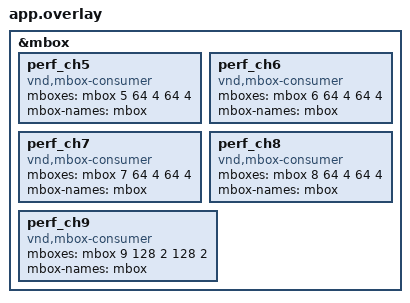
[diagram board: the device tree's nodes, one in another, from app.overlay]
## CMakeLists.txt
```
# SPDX-License-Identifier: Apache-2.0
# perf_test cpu2 (peer): minimal mbox echo companion for the perf_mbox suite.
# The cpu2 console/memory overlays must be injected before find_package().

cmake_minimum_required(VERSION 3.20.0)

set(EXTRA_DTC_OVERLAY_FILE
    ${CMAKE_CURRENT_SOURCE_DIR}/../../../common/cpu2_console_uart5.overlay;
    ${CMAKE_CURRENT_SOURCE_DIR}/../../../common/cpu2_mem_layout.overlay)

find_package(Zephyr REQUIRED HINTS $ENV{ZEPHYR_BASE})
project(cpu2_perf_peer)

target_sources(app PRIVATE src/main.c)

target_include_directories(app PRIVATE
    ${CMAKE_CURRENT_SOURCE_DIR}/../include
    ${CMAKE_CURRENT_SOURCE_DIR}/../../otbn_test/cpu1_otbn_test/src)

# Standalone build: both cores start together, so the 500-frame round trip has
# already happened when peer_alive runs.  The integrated sets never define this
# (their cpu1 sends frames only when the user asks for the perf_mbox suite).
target_compile_definitions(app PRIVATE ITEST_PEER_STANDALONE=1)

include(${CMAKE_CURRENT_SOURCE_DIR}/../../../common/common_sources.cmake)
```

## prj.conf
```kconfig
CONFIG_LOG=y
CONFIG_LOG_MODE_MINIMAL=y

CONFIG_ZTEST=y
CONFIG_ZTEST_ASSERT_VERBOSE=1
CONFIG_ZTEST_VERBOSE_OUTPUT=y
CONFIG_ZTEST_SUMMARY=n
# mbedtls_ls_otbn_rsa_modexp() puts four MBEDTLS_MPI_MAX_SIZE (1 KB) buffers
# on the stack; 4 KB overflowed on hardware (kernel panic).  Leave headroom
# for the OTBN call frame as well.
CONFIG_MAIN_STACK_SIZE=16384

CONFIG_PICOLIBC=y
CONFIG_NEWLIB_LIBC=n
CONFIG_MINIMAL_LIBC=n

CONFIG_MBOX=y
CONFIG_GPIO=y

# ---- OTBN crypto (cpu2 side; cpu1 runs the hardware engines) ----
CONFIG_MBEDTLS=y
CONFIG_MBEDTLS_BUILTIN=y
CONFIG_MBEDTLS_ENABLE_HEAP=y
CONFIG_MBEDTLS_HEAP_SIZE=32768
CONFIG_MBEDTLS_SHA256=y
CONFIG_MBEDTLS_SHA512=y
CONFIG_MBEDTLS_SHA224_SHA256_LINKEDSEMI_OTBN_ALT=y
CONFIG_MBEDTLS_SM3_LINKEDSEMI_OTBN_ALT=y
CONFIG_MBEDTLS_SHA384_SHA512_LINKEDSEMI_OTBN_ALT=y
CONFIG_MBEDTLS_RSA_LINKEDSEMI_OTBN_ALT=y
CONFIG_MBEDTLS_THREADING_LINKEDSEMI_ALT=y
CONFIG_LS_OTBN_OPERATION_TIMEOUT_MS=60000
```

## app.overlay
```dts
/*
 * SPDX-License-Identifier: Apache-2.0
 *
 * perf_test cpu2 (peer) overlay.  Console/memory layout come from the common
 * overlays injected in CMake; this file only adds the mbox consumers.
 * The mboxes first cell is the node's enumeration index under &mbox; the five
 * board-level consumers occupy 0..4, so this project appends 5/6.
 */

&mbox {
	perf_ch5: perf_ch5 {
		compatible = "vnd,mbox-consumer";
		mboxes = <&mbox 5 64 4 64 4>;
		mbox-names = "mbox";
	};

	perf_ch6: perf_ch6 {
		compatible = "vnd,mbox-consumer";
		mboxes = <&mbox 6 64 4 64 4>;
		mbox-names = "mbox";
	};

	perf_ch7: perf_ch7 {
		compatible = "vnd,mbox-consumer";
		mboxes = <&mbox 7 64 4 64 4>;
		mbox-names = "mbox";
	};

	perf_ch8: perf_ch8 {
		compatible = "vnd,mbox-consumer";
		mboxes = <&mbox 8 64 4 64 4>;
		mbox-names = "mbox";
	};

	perf_ch9: perf_ch9 {
		compatible = "vnd,mbox-consumer";
		mboxes = <&mbox 9 128 2 128 2>;
		mbox-names = "mbox";
	};
};
```

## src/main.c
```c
/*
 * SPDX-License-Identifier: Apache-2.0
 *
 * perf_test cpu2 peer.
 *
 * Two jobs:
 *   1. Echo 64-byte frames (perf_ch5 -> perf_ch6) for the cpu1 mbox test.
 *   2. Drive the flash proxy client (perf_ch7/perf_ch8): cpu2 asks the cpu1
 *      server to operate the qspi2 NOR and measures the end-to-end round trip.
 *
 * All test data is reported to cpu1 over perf_ch9 as text lines; cpu1 prints
 * them on its own console with a "PERF_TEST:CTRL:" envelope, so the whole
 * test record is visible on cpu1's UART only.  This core keeps just a boot
 * banner on its local UART.
 */
#include <zephyr/kernel.h>
#include <zephyr/drivers/mbox.h>
#include <errno.h>
#include <stdarg.h>
#include <stdio.h>
#include <string.h>

#if !defined(ITEST_PEER_NO_CRYPTO)
#include "mbedtls/sha256.h"
#include "mbedtls/sha512.h"
#include "mbedtls/sm3_alt.h"
#include "mbedtls_otbn_rsa_mbox.h"
#include "rsa_test_key.h"
#endif

#include "perf_proxy.h"
#include "perf_peer_tele.h"

#if defined(ITEST_ALL_PEER_ZTEST)
/* Provided by integrated/sets/itest_all/cpu2/src/peer_ztest.c: runs the OTBN
 * ztest suites that the integrated image links into this binary. */
extern int itest_all_peer_ztest_run(void);
#endif

#define PERF_MBOX_MAGIC  0x50455246u /* "PERF" */
#define PERF_READY_MAGIC 0x52454144u /* "READY" */
#define PERF_READY_DELAY_MS 600
#define PERF_FRAMES      500
#define TELE_FRAME_SIZE  128

struct perf_msg {
	uint32_t magic;
	uint32_t seq;
	uint8_t payload[56];
};

_Static_assert(sizeof(struct perf_msg) == 64,
	       "perf_msg must match the 64-byte mbox channel width");

/* ------------------------------------------------------------- mbox echo */

#if !defined(ITEST_PEER_NO_ECHO)
/* The integrated driver image keeps its own minimal echo (src/echo_peer.c) and
 * compiles this one out. */

static const struct mbox_dt_spec mbox_rx = MBOX_DT_SPEC_GET(DT_NODELABEL(perf_ch5), mbox);
static const struct mbox_dt_spec mbox_tx = MBOX_DT_SPEC_GET(DT_NODELABEL(perf_ch6), mbox);

K_MSGQ_DEFINE(echo_q, sizeof(struct perf_msg), 16, 4);

static volatile bool peer_started;
static volatile uint32_t echo_count;

static void mbox_rx_cb(const struct device *dev, mbox_channel_id_t channel,
		       void *user_data, struct mbox_msg *msg)
{
	ARG_UNUSED(dev);
	ARG_UNUSED(channel);
	ARG_UNUSED(user_data);

	if (msg == NULL || msg->data == NULL ||
	    msg->size < sizeof(struct perf_msg)) {
		return;
	}
	(void)k_msgq_put(&echo_q, msg->data, K_NO_WAIT);
}

static void echo_thread(void *a, void *b, void *c)
{
	ARG_UNUSED(a);
	ARG_UNUSED(b);
	ARG_UNUSED(c);

	peer_started = true;

	for (;;) {
		struct perf_msg m;
		struct mbox_msg out = {
			.data = &m,
			.size = sizeof(m),
		};

		if (k_msgq_get(&echo_q, &m, K_FOREVER) != 0) {
			continue;
		}

		for (int retry = 0; retry < 10; retry++) {
			if (mbox_send_dt(&mbox_tx, &out) == 0) {
				echo_count++;
				break;
			}
			k_msleep(1);
		}
	}
}

static K_THREAD_STACK_DEFINE(echo_stack, 2048);
static struct k_thread echo_td;
#endif /* !ITEST_PEER_NO_ECHO */

/* ------------------------------------------------------- telemetry sender */

static const struct mbox_dt_spec tele_tx = MBOX_DT_SPEC_GET(DT_NODELABEL(perf_ch9), mbox);

static int tele_send(const char *text)
{
	char buf[TELE_FRAME_SIZE] = { 0 };
	struct mbox_msg msg = {
		.data = buf,
		.size = sizeof(buf),
	};

	strncpy(buf, text, sizeof(buf) - 1);
	for (int i = 0; i < 200; i++) {
		if (mbox_send_dt(&tele_tx, &msg) == 0) {
			return 0;
		}
		k_msleep(1);
	}
	return -EIO;
}

/* Not static: the integrated image (integrated/sets/itest_all/cpu2) relays its
 * own result lines through the same sender. See include/perf_peer_tele.h. */
void tele_line(const char *fmt, ...)
{
	char buf[TELE_FRAME_SIZE];
	va_list ap;

	va_start(ap, fmt);
	vsnprintf(buf, sizeof(buf), fmt, ap);
	va_end(ap);
	(void)tele_send(buf);
}

/* --------------------------------------------------------- proxy client */

#if !defined(ITEST_PEER_NO_PROXY)
/* No flash-proxy channels (perf_ch7/ch8) in the integrated driver image: they
 * do not fit the 4 KB mbox carve-out next to rlog. */
static const struct mbox_dt_spec proxy_tx = MBOX_DT_SPEC_GET(DT_NODELABEL(perf_ch7), mbox);
static const struct mbox_dt_spec proxy_rx = MBOX_DT_SPEC_GET(DT_NODELABEL(perf_ch8), mbox);

/* One 4 KB read comes back as ~103 frames; hold a whole burst. */
K_MSGQ_DEFINE(proxy_q, sizeof(struct perf_proxy_msg), 128, 4);
static uint8_t proxy_buf[PERF_PROXY_SIZE];
static uint8_t proxy_verify[PERF_PROXY_SIZE];
static bool proxy_inited;

static void proxy_rx_cb(const struct device *dev, mbox_channel_id_t channel,
			void *user_data, struct mbox_msg *msg)
{
	ARG_UNUSED(dev);
	ARG_UNUSED(channel);
	ARG_UNUSED(user_data);

	if (msg == NULL || msg->data == NULL ||
	    msg->size < sizeof(struct perf_proxy_msg)) {
		return;
	}
	(void)k_msgq_put(&proxy_q, msg->data, K_NO_WAIT);
}

static int proxy_send(const struct perf_proxy_msg *m)
{
	struct mbox_msg msg = {
		.data = m,
		.size = sizeof(*m),
	};

	for (int i = 0; i < 200; i++) {
		if (mbox_send_dt(&proxy_tx, &msg) == 0) {
			return 0;
		}
		k_msleep(1);
	}
	return -EIO;
}

static int proxy_wait(struct perf_proxy_msg *m, int timeout_ms)
{
	return k_msgq_get(&proxy_q, m, K_MSEC(timeout_ms));
}

static int proxy_simple(uint8_t op, uint32_t offset, uint32_t len)
{
	struct perf_proxy_msg q = {
		.magic = PERF_PROXY_MAGIC,
		.op = op,
		.flags = PERF_PROXY_FLAG_LAST,
		.offset = offset,
		.len = len,
	};
	struct perf_proxy_msg r;

	k_msgq_purge(&proxy_q);
	if (proxy_send(&q) != 0) {
		return -EIO;
	}
	if (proxy_wait(&r, 2000) != 0) {
		return -ETIMEDOUT;
	}
	if (r.magic != PERF_PROXY_MAGIC) {
		return -EIO;
	}
	return (int)r.status;
}

static int proxy_read(uint32_t offset, uint32_t len, uint8_t *out)
{
	struct perf_proxy_msg q = {
		.magic = PERF_PROXY_MAGIC,
		.op = PERF_PROXY_READ,
		.flags = PERF_PROXY_FLAG_LAST,
		.offset = offset,
		.len = len,
	};
	uint32_t got = 0;

	k_msgq_purge(&proxy_q);
	if (proxy_send(&q) != 0) {
		return -EIO;
	}

	for (;;) {
		struct perf_proxy_msg r;

		if (proxy_wait(&r, 2000) != 0) {
			return -ETIMEDOUT;
		}
		if (r.magic != PERF_PROXY_MAGIC || r.op != PERF_PROXY_READ) {
			return -EIO;
		}
		if (r.status != 0) {
			return (int)r.status;
		}
		if (r.len > sizeof(r.data) || got + r.len > len) {
			return -EINVAL;
		}
		memcpy(&out[got], r.data, r.len);
		got += r.len;
		if (r.flags & PERF_PROXY_FLAG_LAST) {
			break;
		}
	}

	return got == len ? 0 : -EIO;
}

static int proxy_write(uint32_t offset, uint32_t len, const uint8_t *data)
{
	struct perf_proxy_msg r;

	k_msgq_purge(&proxy_q);
	for (uint32_t off = 0; off < len; off += PERF_PROXY_CHUNK) {
		uint32_t n = MIN(PERF_PROXY_CHUNK, len - off);
		struct perf_proxy_msg q = {
			.magic = PERF_PROXY_MAGIC,
			.op = PERF_PROXY_WRITE,
			.flags = (off + n >= len) ? PERF_PROXY_FLAG_LAST : 0,
			.offset = offset + off,
			.len = n,
		};

		memcpy(q.data, &data[off], n);
		if (proxy_send(&q) != 0) {
			return -EIO;
		}
	}

	if (proxy_wait(&r, 2000) != 0) {
		return -ETIMEDOUT;
	}
	if (r.magic != PERF_PROXY_MAGIC) {
		return -EIO;
	}
	return (int)r.status;
}

static void proxy_init_once(void)
{
	if (proxy_inited) {
		return;
	}

	(void)mbox_register_callback(proxy_rx.dev, proxy_rx.channel_id,
				     proxy_rx_cb, NULL);
	(void)mbox_set_enabled(proxy_rx.dev, proxy_rx.channel_id, 1);

	for (int i = 0; i < 50; i++) {
		if (proxy_simple(PERF_PROXY_PING, 0, 0) == 0) {
			proxy_inited = true;
			break;
		}
		k_msleep(100);
	}
}

#endif /* !ITEST_PEER_NO_PROXY */

/* -------------------------------------------------------------- test flow */

static void tele_perf(const char *module, const char *op,
		      uint32_t bytes, uint64_t us)
{
	double mb_s;

	if (us == 0) {
		us = 1;
	}
	mb_s = (double)bytes / (double)us;
	tele_line("PERF %s | %s | bytes=%u | MB/s=%.4f | KB/s=%.2f | us=%llu",
		  module, op, (unsigned)bytes, mb_s, mb_s * 1000.0,
		  (unsigned long long)us);
}

static void tele_ops(const char *module, const char *op,
		     uint32_t ops, uint64_t us)
{
	if (us == 0) {
		us = 1;
	}
	tele_line("PERF %s | %s | ops=%u | ops/s=%.2f | us=%llu",
		  module, op, (unsigned)ops,
		  (double)ops * 1000000.0 / (double)us,
		  (unsigned long long)us);
}

#if !defined(ITEST_PEER_NO_PROXY)
static bool run_proxy_erase(void)
{
	uint64_t t0, t1;
	int rc;

	proxy_init_once();
	if (!proxy_inited) {
		return false;
	}

	t0 = k_cycle_get_64();
	rc = proxy_simple(PERF_PROXY_ERASE, PERF_PROXY_OFFSET, PERF_PROXY_SIZE);
	t1 = k_cycle_get_64();

	tele_perf("flash_proxy", "erase", PERF_PROXY_SIZE, k_cyc_to_us_floor64(t1 - t0));
	return rc == 0;
}

static bool run_proxy_read(void)
{
	uint64_t t0, t1;
	int rc;

	proxy_init_once();
	if (!proxy_inited) {
		return false;
	}

	t0 = k_cycle_get_64();
	rc = proxy_read(PERF_PROXY_OFFSET, PERF_PROXY_SIZE, proxy_buf);
	t1 = k_cycle_get_64();

	tele_perf("flash_proxy", "read", PERF_PROXY_SIZE, k_cyc_to_us_floor64(t1 - t0));
	return rc == 0;
}

static bool run_proxy_write(void)
{
	uint64_t t0, t1;
	int rc;

	proxy_init_once();
	if (!proxy_inited) {
		return false;
	}

	for (size_t i = 0; i < PERF_PROXY_SIZE; i++) {
		proxy_buf[i] = (uint8_t)(i * 7u);
	}

	if (proxy_simple(PERF_PROXY_ERASE, PERF_PROXY_OFFSET,
			 PERF_PROXY_SIZE) != 0) {
		return false;
	}

	t0 = k_cycle_get_64();
	rc = proxy_write(PERF_PROXY_OFFSET, PERF_PROXY_SIZE, proxy_buf);
	t1 = k_cycle_get_64();

	tele_perf("flash_proxy", "write", PERF_PROXY_SIZE, k_cyc_to_us_floor64(t1 - t0));

	if (rc != 0) {
		return false;
	}
	if (proxy_read(PERF_PROXY_OFFSET, PERF_PROXY_SIZE, proxy_verify) != 0) {
		return false;
	}
	return memcmp(proxy_buf, proxy_verify, PERF_PROXY_SIZE) == 0;
}

#endif /* !ITEST_PEER_NO_PROXY */

#if defined(ITEST_PEER_STANDALONE)
/* Only meaningful standalone: there both cores start together, so cpu1 has
 * already pushed the 500 frames by the time this runs.  In an integrated image
 * cpu1 sends frames only when the user runs the perf_mbox suite, so this would
 * just burn its 30 s timeout and report a false FAIL. */
static bool run_peer_alive(void)
{
	int64_t deadline = k_uptime_get() + 30000;

	if (!peer_started) {
		return false;
	}

	while (echo_count < PERF_FRAMES && k_uptime_get() < deadline) {
		k_msleep(10);
	}
	return echo_count == PERF_FRAMES;
}
#endif /* ITEST_PEER_STANDALONE */

/* parse_ztest's native token form requires the duration suffix. */
static void report(const char *name, bool ok, int64_t elapsed_ms, bool *all_ok)
{
	tele_line("%s - %s in %.3f seconds", ok ? "PASS" : "FAIL", name,
		  (double)elapsed_ms / 1000.0);
	if (!ok) {
		*all_ok = false;
	}
}

/* ------------------------------------------------- OTBN crypto (cpu2) */

#if !defined(ITEST_PEER_NO_CRYPTO)
/* The integrated driver image (integrated/sets/itest_all/cpu2) leaves the
 * crypto out: it has no OTBN configuration, and crypto lives in the dedicated
 * itest_crypto set. */

#define CRYPTO_BUF_SIZE (KB(32) + 32)
static uint8_t crypto_buf[CRYPTO_BUF_SIZE] __aligned(32);
static const size_t crypto_sizes[] = { KB(1), KB(4), KB(16), KB(32) };

static bool digest_sha256(const uint8_t *in, size_t len, uint8_t out[32])
{
	mbedtls_sha256_context c;
	int rc;

	mbedtls_sha256_init(&c);
	rc = mbedtls_sha256_starts(&c, 0);
	rc |= mbedtls_sha256_update(&c, in, len);
	rc |= mbedtls_sha256_finish(&c, out);
	mbedtls_sha256_free(&c);
	return rc == 0;
}

static bool digest_sha512(const uint8_t *in, size_t len, uint8_t out[64])
{
	mbedtls_sha512_context c;
	int rc;

	mbedtls_sha512_init(&c);
	rc = mbedtls_sha512_starts(&c, 0);
	rc |= mbedtls_sha512_update(&c, in, len);
	rc |= mbedtls_sha512_finish(&c, out);
	mbedtls_sha512_free(&c);
	return rc == 0;
}

static bool digest_sm3(const uint8_t *in, size_t len, uint8_t out[32])
{
	mbedtls_sm3_context c;
	int rc;

	mbedtls_sm3_init(&c);
	rc = mbedtls_sm3_starts(&c);
	rc |= mbedtls_sm3_update(&c, in, len);
	rc |= mbedtls_sm3_finish(&c, out);
	mbedtls_sm3_free(&c);
	return rc == 0;
}

static bool run_sha256_otbn(bool unaligned)
{
	uint8_t ref[32], out[32];
	const char *name = unaligned ? "sha256_otbn_unaligned" : "sha256_otbn";

	memset(crypto_buf, 0x5A, sizeof(crypto_buf));
	for (size_t s = 0; s < ARRAY_SIZE(crypto_sizes); s++) {
		size_t size = crypto_sizes[s];
		const uint8_t *in = unaligned ? crypto_buf + 1 : crypto_buf;
		mbedtls_sha256_context c;
		uint64_t t0, t1;
		int rc;

		if (!digest_sha256(crypto_buf, size, ref)) {
			return false;
		}
		mbedtls_sha256_init(&c);
		rc = mbedtls_sha256_starts(&c, 0);
		t0 = k_cycle_get_64();
		rc |= mbedtls_sha256_update(&c, in, size);
		rc |= mbedtls_sha256_finish(&c, out);
		t1 = k_cycle_get_64();
		mbedtls_sha256_free(&c);
		if (rc != 0 || memcmp(ref, out, sizeof(out)) != 0) {
			return false;
		}
		tele_perf("crypto", name, size, k_cyc_to_us_floor64(t1 - t0));
	}
	return true;
}

static bool run_sha512_otbn(bool unaligned)
{
	uint8_t ref[64], out[64];
	const char *name = unaligned ? "sha512_otbn_unaligned" : "sha512_otbn";

	memset(crypto_buf, 0x5A, sizeof(crypto_buf));
	for (size_t s = 0; s < ARRAY_SIZE(crypto_sizes); s++) {
		size_t size = crypto_sizes[s];
		const uint8_t *in = unaligned ? crypto_buf + 1 : crypto_buf;
		mbedtls_sha512_context c;
		uint64_t t0, t1;
		int rc;

		if (!digest_sha512(crypto_buf, size, ref)) {
			return false;
		}
		mbedtls_sha512_init(&c);
		rc = mbedtls_sha512_starts(&c, 0);
		t0 = k_cycle_get_64();
		rc |= mbedtls_sha512_update(&c, in, size);
		rc |= mbedtls_sha512_finish(&c, out);
		t1 = k_cycle_get_64();
		mbedtls_sha512_free(&c);
		if (rc != 0 || memcmp(ref, out, sizeof(out)) != 0) {
			return false;
		}
		tele_perf("crypto", name, size, k_cyc_to_us_floor64(t1 - t0));
	}
	return true;
}

static bool run_sm3_otbn(bool unaligned)
{
	uint8_t ref[32], out[32];
	const char *name = unaligned ? "sm3_otbn_unaligned" : "sm3_otbn";

	memset(crypto_buf, 0x5A, sizeof(crypto_buf));
	for (size_t s = 0; s < ARRAY_SIZE(crypto_sizes); s++) {
		size_t size = crypto_sizes[s];
		const uint8_t *in = unaligned ? crypto_buf + 1 : crypto_buf;
		mbedtls_sm3_context c;
		uint64_t t0, t1;
		int rc;

		if (!digest_sm3(crypto_buf, size, ref)) {
			return false;
		}
		mbedtls_sm3_init(&c);
		rc = mbedtls_sm3_starts(&c);
		t0 = k_cycle_get_64();
		rc |= mbedtls_sm3_update(&c, in, size);
		rc |= mbedtls_sm3_finish(&c, out);
		t1 = k_cycle_get_64();
		mbedtls_sm3_free(&c);
		if (rc != 0 || memcmp(ref, out, sizeof(out)) != 0) {
			return false;
		}
		tele_perf("crypto", name, size, k_cyc_to_us_floor64(t1 - t0));
	}
	return true;
}

static bool run_rsa_modexp_otbn(void)
{
	static uint8_t out[256];
	uint64_t t0, t1;
	int rc;

	t0 = k_cycle_get_64();
	rc = mbedtls_ls_otbn_rsa_modexp(rsa2048_ciphertext, out,
					rsa2048_d, rsa2048_n, 256, false);
	t1 = k_cycle_get_64();
	if (rc != 0) {
		return false;
	}
	tele_ops("crypto", "rsa2048_modexp", 1, k_cyc_to_us_floor64(t1 - t0));
	return true;
}
#endif /* !ITEST_PEER_NO_CRYPTO */

#if defined(ITEST_PEER_NO_MAIN)
/*
 * On-demand entry for the integrated driver image (itest_all/cpu2).
 *
 * The image must not run crypto at boot, so this replaces test_main(): cpu1
 * asks for the OTBN throughput sequence with `itest peer otbn`, and the rates
 * are relayed over perf_ch9 exactly like the standalone project.
 */
int perf_peer_otbn_run(void)
{
	bool all_ok = true;
	int64_t t0;

	tele_line("ITEST_PEER_RUN otbn_perf");

	t0 = k_uptime_get();
	report("sha256_otbn", run_sha256_otbn(false), k_uptime_get() - t0, &all_ok);
	t0 = k_uptime_get();
	report("sha256_otbn_unaligned", run_sha256_otbn(true), k_uptime_get() - t0, &all_ok);
	t0 = k_uptime_get();
	report("sha512_otbn", run_sha512_otbn(false), k_uptime_get() - t0, &all_ok);
	t0 = k_uptime_get();
	report("sha512_otbn_unaligned", run_sha512_otbn(true), k_uptime_get() - t0, &all_ok);
	t0 = k_uptime_get();
	report("sm3_otbn", run_sm3_otbn(false), k_uptime_get() - t0, &all_ok);
	t0 = k_uptime_get();
	report("sm3_otbn_unaligned", run_sm3_otbn(true), k_uptime_get() - t0, &all_ok);
	t0 = k_uptime_get();
	report("rsa2048_modexp", run_rsa_modexp_otbn(), k_uptime_get() - t0, &all_ok);

	tele_line("ITEST_PEER_DONE otbn_perf %s", all_ok ? "PASS" : "FAIL");
	return all_ok ? 0 : 1;
}
#else
void test_main(void)
{
	bool all_ok = true;

	printk("[CPU2 PERF_PEER] mbox echo + flash proxy peer started\n");

	/* The boot marker is relayed too, so the harness sees a CTRL stream on
	 * cpu1's console. */
	tele_line("ZT_BOOT CTRL");

	(void)mbox_register_callback(mbox_rx.dev, mbox_rx.channel_id,
				     mbox_rx_cb, NULL);
	(void)mbox_set_enabled(mbox_rx.dev, mbox_rx.channel_id, 1);

	k_thread_create(&echo_td, echo_stack, K_THREAD_STACK_SIZEOF(echo_stack),
			echo_thread, NULL, NULL, NULL,
			K_PRIO_PREEMPT(7), 0, K_NO_WAIT);
	k_thread_name_set(&echo_td, "perf_echo");

	k_msleep(PERF_READY_DELAY_MS);

	struct perf_msg ready = {
		.magic = PERF_READY_MAGIC,
		.seq = 0,
	};
	struct mbox_msg msg = {
		.data = &ready,
		.size = sizeof(ready),
	};

	(void)mbox_send_dt(&mbox_tx, &msg);

	int64_t t0;

#if !defined(ITEST_PEER_NO_CRYPTO)
	t0 = k_uptime_get();
	report("sha256_otbn", run_sha256_otbn(false), k_uptime_get() - t0, &all_ok);
	t0 = k_uptime_get();
	report("sha256_otbn_unaligned", run_sha256_otbn(true), k_uptime_get() - t0, &all_ok);
	t0 = k_uptime_get();
	report("sha512_otbn", run_sha512_otbn(false), k_uptime_get() - t0, &all_ok);
	t0 = k_uptime_get();
	report("sha512_otbn_unaligned", run_sha512_otbn(true), k_uptime_get() - t0, &all_ok);
	t0 = k_uptime_get();
	report("sm3_otbn", run_sm3_otbn(false), k_uptime_get() - t0, &all_ok);
	t0 = k_uptime_get();
	report("sm3_otbn_unaligned", run_sm3_otbn(true), k_uptime_get() - t0, &all_ok);
	t0 = k_uptime_get();
	report("rsa2048_modexp", run_rsa_modexp_otbn(), k_uptime_get() - t0, &all_ok);
#endif /* !ITEST_PEER_NO_CRYPTO */

	t0 = k_uptime_get();
	report("proxy_erase", run_proxy_erase(), k_uptime_get() - t0, &all_ok);
	t0 = k_uptime_get();
	report("proxy_read", run_proxy_read(), k_uptime_get() - t0, &all_ok);
	t0 = k_uptime_get();
	report("proxy_write", run_proxy_write(), k_uptime_get() - t0, &all_ok);
#if defined(ITEST_PEER_STANDALONE)
	t0 = k_uptime_get();
	report("peer_alive", run_peer_alive(), k_uptime_get() - t0, &all_ok);
#endif

#if !defined(ITEST_ALL_PEER_ZTEST)
	tele_line("PROJECT EXECUTION %s", all_ok ? "SUCCESSFUL" : "FAILED");
#else
	/* The OTBN ztest run has not happened yet, so this is not a verdict:
	 * announcing SUCCESSFUL here would leave a pass token in the log even
	 * when the suites then fail.  Only the line after the ztest run counts. */
	tele_line("ITEST_PEER_PHASE perf_done %s", all_ok ? "PASS" : "FAIL");
#endif

#if defined(ITEST_ALL_PEER_ZTEST)
	/* Integrated image: also run the OTBN suites (otbn_test, otbn_selftest,
	 * keygen, mbedtls-on-OTBN).  They live here because the OTBN ALT and the
	 * hardware ALT cannot share one ELF.  Their verdict is folded into this
	 * core's overall result; per-suite lines follow on the same relay. */
	if (itest_all_peer_ztest_run() != 0) {
		all_ok = false;
	}
	tele_line("PROJECT EXECUTION %s", all_ok ? "SUCCESSFUL" : "FAILED");
#endif

	k_sleep(K_FOREVER);
}
#endif /* !ITEST_PEER_NO_MAIN */
```
